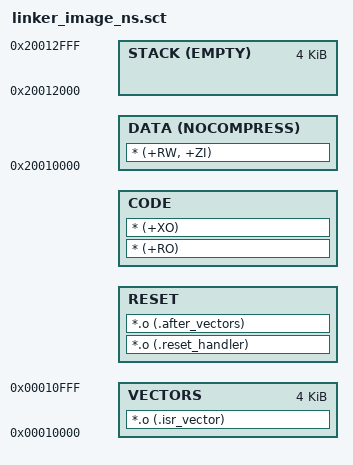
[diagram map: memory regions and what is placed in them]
; non-secure code is placed in this secure address range
LR_IROM1 0x00010000 0x00010000  {

  VECTORS 0x00010000 0x1000  {  ; load region = execution region.
    *.o (.isr_vector)
  }
  
  RESET +0  {
    *.o (.reset_handler)
    *.o (.after_vectors)
  }
  
  CODE +0  {  ; load region = execution region.
     * (+RO)
     * (+XO)
  }
  
  DATA 0x20010000 NOCOMPRESS  {  ; RW data
   * (+RW, +ZI)
  }
  
  STACK 0x20012000 EMPTY 0x1000  {}
}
